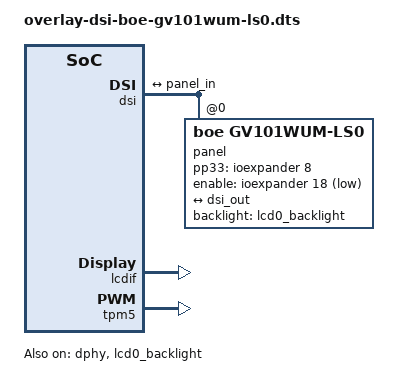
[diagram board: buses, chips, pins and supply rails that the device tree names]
/*
 * Copyright (C) 2022 Avnet Embedded
 *
 * This program is free software; you can redistribute it and/or
 * modify it under the terms of the GNU General Public License as
 * published by the Free Software Foundation version 2.
 *
 * This program is distributed "as is" WITHOUT ANY WARRANTY of any
 * kind, whether express or implied; without even the implied warranty
 * of MERCHANTABILITY or FITNESS FOR A PARTICULAR PURPOSE.  See the
 * GNU General Public License for more details.
 */

/dts-v1/;
/plugin/;

#include <dt-bindings/gpio/gpio.h>

/ {
	fragment@4000 {
		target = <&dsi>;
		__overlay__ {
			#address-cells = <1>;
			#size-cells = <0>;
			status = "okay";

			panel@0 {
				reg = <0>;
				compatible = "boe,gv101wum-ls0";
				backlight = <&lcd0_backlight>;
				pp33-gpios = <&ioexpander 8 GPIO_ACTIVE_HIGH>;
				enable-gpios = <&ioexpander 18 GPIO_ACTIVE_LOW>;
				status = "okay";

				port {
					panel_in: endpoint {
						remote-endpoint = <&dsi_out>;
					};
				};
			};

			ports {
				#address-cells = <1>;
				#size-cells = <0>;

				port@1 {
					reg = <1>;
					dsi_out: endpoint {
						remote-endpoint = <&panel_in>;
					};
				};
			};
		};
	};

	fragment@4001 {
		target = <&lcdif>;
		__overlay__ {
			assigned-clock-rates = <498000000>, <71142857>, <400000000>, <133333333>;
			status = "okay";
		};
	};

	fragment@4002 {
		target = <&dphy>;
		__overlay__ {
			status = "okay";
		};
	};

	fragment@4004 {
		target = <&tpm5>;
		__overlay__ {
			status = "okay";
		};
	};

	fragment@4005 {
		target = <&lcd0_backlight>;
		__overlay__ {
			status = "okay";
		};
	};
};
